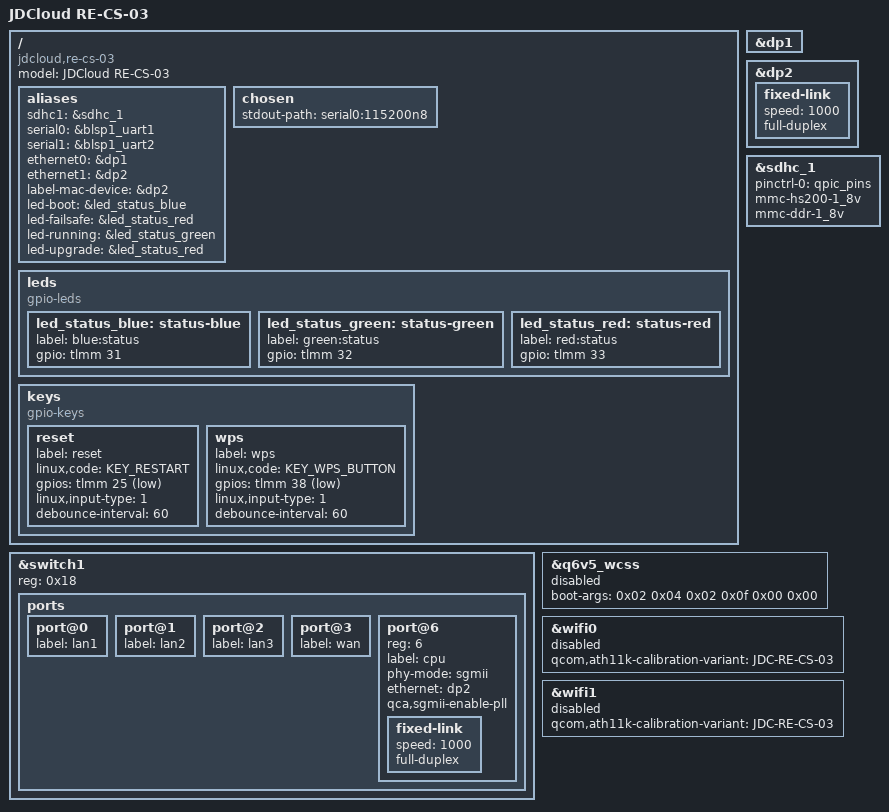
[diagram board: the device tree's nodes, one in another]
// SPDX-License-Identifier: GPL-2.0-or-later OR MIT

/dts-v1/;

#include "ipq5018.dtsi"
#include "ipq5018-ess.dtsi"
#include "ipq5018-nss.dtsi"
#include "ipq5018-common.dtsi"

#include <dt-bindings/gpio/gpio.h>
#include <dt-bindings/input/input.h>
#include <dt-bindings/leds/common.h>

/ {
	model = "JDCloud RE-CS-03";
	compatible = "jdcloud,re-cs-03", "qcom,ipq5018";

	aliases {
		sdhc1 = &sdhc_1;
		serial0 = &blsp1_uart1;
		serial1 = &blsp1_uart2;

		ethernet0 = &dp1;
		ethernet1 = &dp2;
		label-mac-device = &dp2;

		led-boot = &led_status_blue;
		led-failsafe = &led_status_red;
		led-running = &led_status_green;
		led-upgrade = &led_status_red;
	};

	chosen {
		stdout-path = "serial0:115200n8";
	};

	leds {
		compatible = "gpio-leds";

		led_status_blue: status-blue {
			label = "blue:status";
			gpio = <&tlmm 31 GPIO_ACTIVE_HIGH>;
		};

		led_status_green: status-green {
			label = "green:status";
			gpio = <&tlmm 32 GPIO_ACTIVE_HIGH>;
		};

		led_status_red: status-red {
			label = "red:status";
			gpio = <&tlmm 33 GPIO_ACTIVE_HIGH>;
		};
	};

	keys {
		compatible = "gpio-keys";

		reset {
			label = "reset";
			linux,code = <KEY_RESTART>;
			gpios = <&tlmm 25 GPIO_ACTIVE_LOW>;
			linux,input-type = <1>;
			debounce-interval = <60>;
		};

		wps {
			label = "wps";
			linux,code = <KEY_WPS_BUTTON>;
			gpios = <&tlmm 38 GPIO_ACTIVE_LOW>;
			linux,input-type = <1>;
			debounce-interval = <60>;
		};
	};
};

&dp1 {
	status = "okay";
};

&dp2 {
	status = "okay";

	fixed-link {
		speed = <1000>;
		full-duplex;
	};
};

&switch1 {
	reg = <0x18>;

	ports {
		port@0 {
			label = "lan1";
		};

		port@1 {
			label = "lan2";
		};

		port@2 {
			label = "lan3";
		};

		port@3 {
			label = "wan";
		};

		port@6 {
			reg = <6>;
			label = "cpu";
			phy-mode = "sgmii";
			ethernet = <&dp2>;
			qca,sgmii-enable-pll;

			fixed-link {
				speed = <1000>;
				full-duplex;
			};
		};
	};
};

&sdhc_1 {
	status = "okay";

	pinctrl-0 = <&qpic_pins>;
	pinctrl-names = "default";

	/delete-property/ mmc-hs400-1_8v;
	mmc-hs200-1_8v;
	mmc-ddr-1_8v;
};

&q6v5_wcss {
	status = "okey";
	boot-args = <0x02 0x04 0x02 0x0f 0x00 0x00>;
};

&wifi0 {
	status = "okey";
	qcom,ath11k-calibration-variant = "JDC-RE-CS-03";
};

&wifi1 {
	status = "okey";
	qcom,ath11k-calibration-variant = "JDC-RE-CS-03";
};
